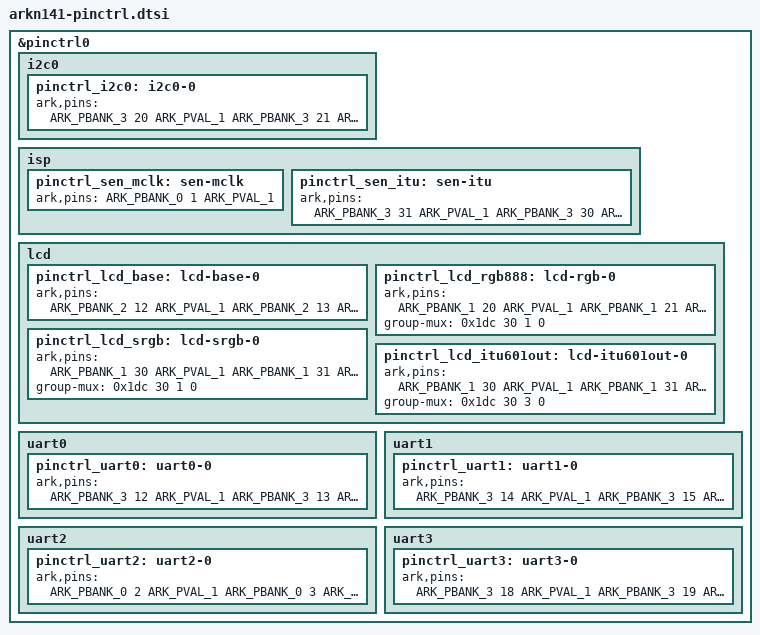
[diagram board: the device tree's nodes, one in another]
#include <dt-bindings/pinctrl/ark-pinfunc.h>

&pinctrl0 {
    i2c0 {
        pinctrl_i2c0: i2c0-0 {
            ark,pins =
                <ARK_PBANK_3 20 ARK_PVAL_1		/* i2c0 scl */
                    ARK_PBANK_3 21 ARK_PVAL_1>;	/* i2c0 sda */
        };
    };

	isp {
		pinctrl_sen_mclk: sen-mclk {
			ark,pins =
                <ARK_PBANK_0 1 ARK_PVAL_1>;
		};

		pinctrl_sen_itu: sen-itu {
			ark,pins =
                <ARK_PBANK_3 31 ARK_PVAL_1		/* clk */
                    ARK_PBANK_3 30 ARK_PVAL_1		/* vsync */
                    ARK_PBANK_3 29 ARK_PVAL_1		/* hsync */
                    //ARK_PBANK_3 28 ARK_PVAL_1		/* d0 */
                    //ARK_PBANK_0 4 ARK_PVAL_1		/* d1 */
                    ARK_PBANK_0 5 ARK_PVAL_1		/* d2 */
                    ARK_PBANK_0 6 ARK_PVAL_1		/* d3 */
                    ARK_PBANK_0 7 ARK_PVAL_1		/* d4 */
                    ARK_PBANK_0 8 ARK_PVAL_1		/* d5 */
                    ARK_PBANK_0 9 ARK_PVAL_1		/* d6 */
                    ARK_PBANK_0 10 ARK_PVAL_1		/* d7 */
                    ARK_PBANK_0 11 ARK_PVAL_1		/* d8 */
                    ARK_PBANK_0 12 ARK_PVAL_1		/* d9 */
                    ARK_PBANK_0 13 ARK_PVAL_1		/* d10 */
                    ARK_PBANK_0 14 ARK_PVAL_1>;		/* d11 */
		};
	};

	lcd {
        pinctrl_lcd_base: lcd-base-0 {
            ark,pins =
                <ARK_PBANK_2 12 ARK_PVAL_1		/* de */
                    ARK_PBANK_2 13 ARK_PVAL_1		/* clk */
                    ARK_PBANK_2 14 ARK_PVAL_1  	/* vsync */
                    ARK_PBANK_2 15 ARK_PVAL_1>;	/* hsync */
        };

        pinctrl_lcd_rgb888: lcd-rgb-0 {
            ark,pins =
                <ARK_PBANK_1 20 ARK_PVAL_1		/* r0 */
                    ARK_PBANK_1 21 ARK_PVAL_1		/* r1 */
                    ARK_PBANK_1 22 ARK_PVAL_1		/* r2 */
                    ARK_PBANK_1 23 ARK_PVAL_1		/* r3 */
                    ARK_PBANK_1 24 ARK_PVAL_1		/* r4 */
                    ARK_PBANK_1 25 ARK_PVAL_1		/* r5 */
                    ARK_PBANK_1 26 ARK_PVAL_1		/* r6 */
                    ARK_PBANK_1 27 ARK_PVAL_1		/* r7 */
                    ARK_PBANK_1 28 ARK_PVAL_1		/* g0 */
                    ARK_PBANK_1 29 ARK_PVAL_1		/* g1 */
                    ARK_PBANK_1 30 ARK_PVAL_1		/* g2 */
                    ARK_PBANK_1 31 ARK_PVAL_1		/* g3 */
                    ARK_PBANK_2 0 ARK_PVAL_1		/* g4 */
                    ARK_PBANK_2 1 ARK_PVAL_1		/* g5 */
                    ARK_PBANK_2 2 ARK_PVAL_1		/* g6 */
                    ARK_PBANK_2 3 ARK_PVAL_1		/* g7 */
                    ARK_PBANK_2 4 ARK_PVAL_1		/* b0 */
                    ARK_PBANK_2 5 ARK_PVAL_1		/* b1 */
                    ARK_PBANK_2 6 ARK_PVAL_1		/* b2 */
                    ARK_PBANK_2 7 ARK_PVAL_1		/* b3 */
                    ARK_PBANK_2 8 ARK_PVAL_1		/* b4 */
                    ARK_PBANK_2 9 ARK_PVAL_1		/* b5 */
                    ARK_PBANK_2 10 ARK_PVAL_1		/* b6 */
                    ARK_PBANK_2 11 ARK_PVAL_1>;	/* b7 */
			group-mux = <0x1dc 30 1 0>;
        };

		pinctrl_lcd_srgb: lcd-srgb-0 {
            ark,pins =
                <ARK_PBANK_1 30 ARK_PVAL_1		/* d0 */
                 ARK_PBANK_1 31 ARK_PVAL_1		/* d1 */
                 ARK_PBANK_2 0 ARK_PVAL_1		/* d2 */
                 ARK_PBANK_2 1 ARK_PVAL_1		/* d3 */
                 ARK_PBANK_2 2 ARK_PVAL_1		/* d4 */
                 ARK_PBANK_2 3 ARK_PVAL_1		/* d5 */
                 ARK_PBANK_2 4 ARK_PVAL_1		/* d6 */
                 ARK_PBANK_2 5 ARK_PVAL_1>;		/* d7 */
			group-mux = <0x1dc 30 1 0>;
		};

		pinctrl_lcd_itu601out: lcd-itu601out-0 {
            ark,pins =
                <ARK_PBANK_1 30 ARK_PVAL_1		/* d0 */
                 ARK_PBANK_1 31 ARK_PVAL_1		/* d1 */
                 ARK_PBANK_2 0 ARK_PVAL_1		/* d2 */
                 ARK_PBANK_2 1 ARK_PVAL_1		/* d3 */
                 ARK_PBANK_2 2 ARK_PVAL_1		/* d4 */
                 ARK_PBANK_2 3 ARK_PVAL_1		/* d5 */
                 ARK_PBANK_2 4 ARK_PVAL_1		/* d6 */
                 ARK_PBANK_2 5 ARK_PVAL_1>;		/* d7 */
			group-mux = <0x1dc 30 3 0>;
		};
    };

    uart0 {
        pinctrl_uart0: uart0-0 {
            ark,pins =
            <ARK_PBANK_3 12 ARK_PVAL_1      /* uart0 rx */
            ARK_PBANK_3 13 ARK_PVAL_1>;     /* uart0 tx */
        };
    };

	uart1 {
        pinctrl_uart1: uart1-0 {
            ark,pins =
                <ARK_PBANK_3 14 ARK_PVAL_1      /* uart1 rx */
                    ARK_PBANK_3 15 ARK_PVAL_1>; /* uart1 tx */
            };
    };

    uart2 {
        pinctrl_uart2: uart2-0 {
            ark,pins =
                <ARK_PBANK_0 2 ARK_PVAL_1       /* uart2 rx */
                    ARK_PBANK_0 3 ARK_PVAL_1>;  /* uart2 tx */
        };
    };

    uart3 {
        pinctrl_uart3: uart3-0 {
            ark,pins =
                <ARK_PBANK_3 18 ARK_PVAL_1      /* uart3 rx */
                    ARK_PBANK_3 19 ARK_PVAL_1>; /* uart3 tx */
        };
    };
};
